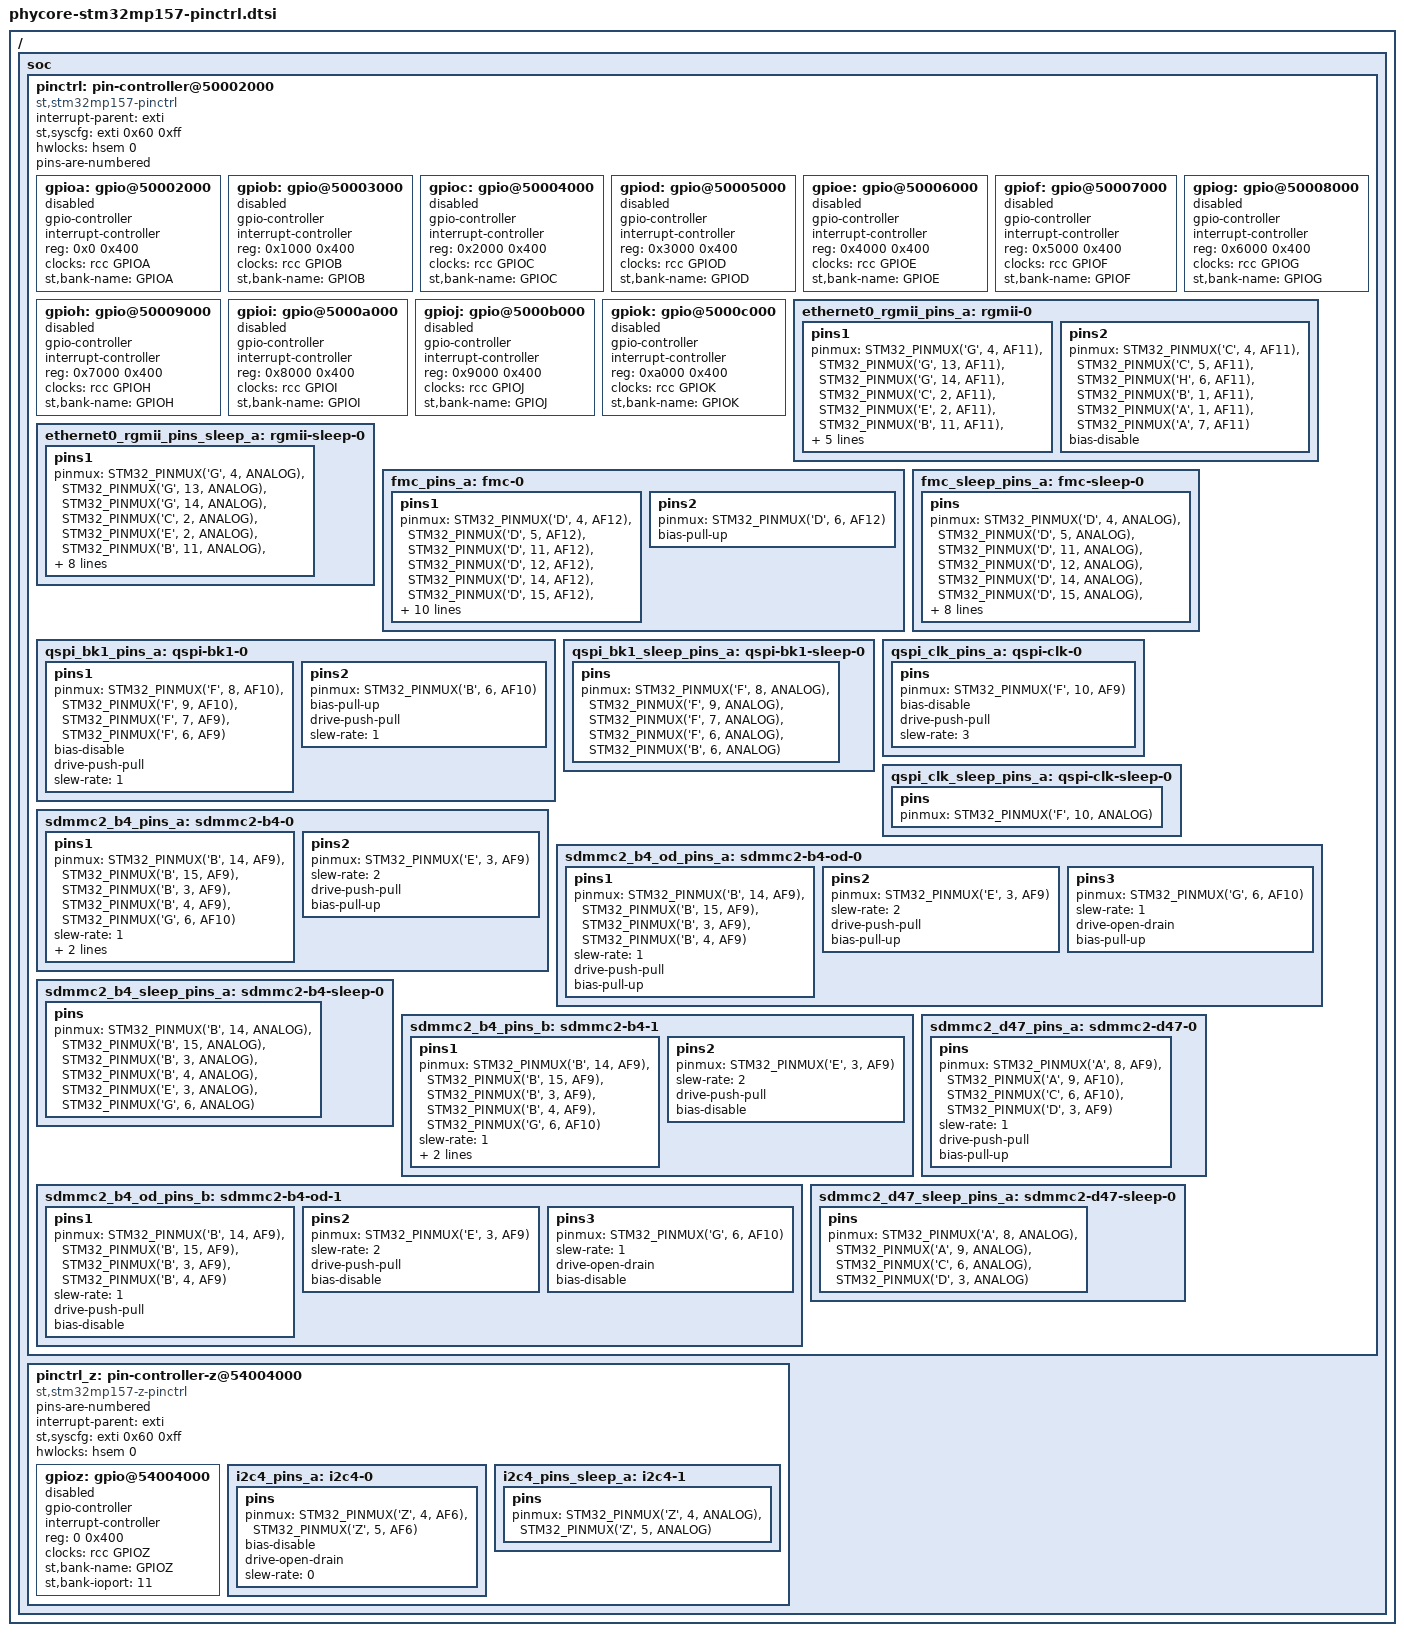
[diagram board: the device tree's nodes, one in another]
// SPDX-License-Identifier: (GPL-2.0+ OR BSD-3-Clause)
/*
 * Copyright (C) PHYTEC GmbH 2019-2020 - All Rights Reserved
 * Author: Dom VOVARD <dom.vovard@linrt.com>.
 */

#include <dt-bindings/pinctrl/stm32-pinfunc.h>

/ {
	soc {
		pinctrl: pin-controller@50002000 {
			#address-cells = <1>;
			#size-cells = <1>;
			compatible = "st,stm32mp157-pinctrl";
			ranges = <0 0x50002000 0xa400>;
			interrupt-parent = <&exti>;
			st,syscfg = <&exti 0x60 0xff>;
			hwlocks = <&hsem 0>;
			pins-are-numbered;

			gpioa: gpio@50002000 {
				gpio-controller;
				#gpio-cells = <2>;
				interrupt-controller;
				#interrupt-cells = <2>;
				reg = <0x0 0x400>;
				clocks = <&rcc GPIOA>;
				st,bank-name = "GPIOA";
				status = "disabled";
			};

			gpiob: gpio@50003000 {
				gpio-controller;
				#gpio-cells = <2>;
				interrupt-controller;
				#interrupt-cells = <2>;
				reg = <0x1000 0x400>;
				clocks = <&rcc GPIOB>;
				st,bank-name = "GPIOB";
				status = "disabled";
			};

			gpioc: gpio@50004000 {
				gpio-controller;
				#gpio-cells = <2>;
				interrupt-controller;
				#interrupt-cells = <2>;
				reg = <0x2000 0x400>;
				clocks = <&rcc GPIOC>;
				st,bank-name = "GPIOC";
				status = "disabled";
			};

			gpiod: gpio@50005000 {
				gpio-controller;
				#gpio-cells = <2>;
				interrupt-controller;
				#interrupt-cells = <2>;
				reg = <0x3000 0x400>;
				clocks = <&rcc GPIOD>;
				st,bank-name = "GPIOD";
				status = "disabled";
			};

			gpioe: gpio@50006000 {
				gpio-controller;
				#gpio-cells = <2>;
				interrupt-controller;
				#interrupt-cells = <2>;
				reg = <0x4000 0x400>;
				clocks = <&rcc GPIOE>;
				st,bank-name = "GPIOE";
				status = "disabled";
			};

			gpiof: gpio@50007000 {
				gpio-controller;
				#gpio-cells = <2>;
				interrupt-controller;
				#interrupt-cells = <2>;
				reg = <0x5000 0x400>;
				clocks = <&rcc GPIOF>;
				st,bank-name = "GPIOF";
				status = "disabled";
			};

			gpiog: gpio@50008000 {
				gpio-controller;
				#gpio-cells = <2>;
				interrupt-controller;
				#interrupt-cells = <2>;
				reg = <0x6000 0x400>;
				clocks = <&rcc GPIOG>;
				st,bank-name = "GPIOG";
				status = "disabled";
			};

			gpioh: gpio@50009000 {
				gpio-controller;
				#gpio-cells = <2>;
				interrupt-controller;
				#interrupt-cells = <2>;
				reg = <0x7000 0x400>;
				clocks = <&rcc GPIOH>;
				st,bank-name = "GPIOH";
				status = "disabled";
			};

			gpioi: gpio@5000a000 {
				gpio-controller;
				#gpio-cells = <2>;
				interrupt-controller;
				#interrupt-cells = <2>;
				reg = <0x8000 0x400>;
				clocks = <&rcc GPIOI>;
				st,bank-name = "GPIOI";
				status = "disabled";
			};

			gpioj: gpio@5000b000 {
				gpio-controller;
				#gpio-cells = <2>;
				interrupt-controller;
				#interrupt-cells = <2>;
				reg = <0x9000 0x400>;
				clocks = <&rcc GPIOJ>;
				st,bank-name = "GPIOJ";
				status = "disabled";
			};

			gpiok: gpio@5000c000 {
				gpio-controller;
				#gpio-cells = <2>;
				interrupt-controller;
				#interrupt-cells = <2>;
				reg = <0xa000 0x400>;
				clocks = <&rcc GPIOK>;
				st,bank-name = "GPIOK";
				status = "disabled";
			};

			ethernet0_rgmii_pins_a: rgmii-0 {
				pins1 {
					pinmux = <STM32_PINMUX('G', 4, AF11)>, /* ETH_RGMII_GTX_CLK */
						 <STM32_PINMUX('G', 13, AF11)>, /* ETH_RGMII_TXD0 */
						 <STM32_PINMUX('G', 14, AF11)>, /* ETH_RGMII_TXD1 */
						 <STM32_PINMUX('C', 2, AF11)>, /* ETH_RGMII_TXD2 */
						 <STM32_PINMUX('E', 2, AF11)>, /* ETH_RGMII_TXD3 */
						 <STM32_PINMUX('B', 11, AF11)>, /* ETH_RGMII_TX_CTL */
						 <STM32_PINMUX('A', 2, AF11)>, /* ETH_MDIO */
						 <STM32_PINMUX('C', 1, AF11)>; /* ETH_MDC */
					bias-disable;
					drive-push-pull;
					slew-rate = <2>;
				};
				pins2 {
					pinmux = <STM32_PINMUX('C', 4, AF11)>, /* ETH_RGMII_RXD0 */
						 <STM32_PINMUX('C', 5, AF11)>, /* ETH_RGMII_RXD1 */
						 <STM32_PINMUX('H', 6, AF11)>, /* ETH_RGMII_RXD2 */
						 <STM32_PINMUX('B', 1, AF11)>, /* ETH_RGMII_RXD3 */
						 <STM32_PINMUX('A', 1, AF11)>, /* ETH_RGMII_RX_CLK */
						 <STM32_PINMUX('A', 7, AF11)>; /* ETH_RGMII_RX_CTL */
					bias-disable;
				};
			};

			ethernet0_rgmii_pins_sleep_a: rgmii-sleep-0 {
				pins1 {
					pinmux = <STM32_PINMUX('G', 4, ANALOG)>, /* ETH_RGMII_GTX_CLK */
						 <STM32_PINMUX('G', 13, ANALOG)>, /* ETH_RGMII_TXD0 */
						 <STM32_PINMUX('G', 14, ANALOG)>, /* ETH_RGMII_TXD1 */
						 <STM32_PINMUX('C', 2, ANALOG)>, /* ETH_RGMII_TXD2 */
						 <STM32_PINMUX('E', 2, ANALOG)>, /* ETH_RGMII_TXD3 */
						 <STM32_PINMUX('B', 11, ANALOG)>, /* ETH_RGMII_TX_CTL */
						 <STM32_PINMUX('A', 2, ANALOG)>, /* ETH_MDIO */
						 <STM32_PINMUX('C', 1, ANALOG)>, /* ETH_MDC */
						 <STM32_PINMUX('C', 4, ANALOG)>, /* ETH_RGMII_RXD0 */
						 <STM32_PINMUX('C', 5, ANALOG)>, /* ETH_RGMII_RXD1 */
						 <STM32_PINMUX('H', 6, ANALOG)>, /* ETH_RGMII_RXD2 */
						 <STM32_PINMUX('B', 1, ANALOG)>, /* ETH_RGMII_RXD3 */
						 <STM32_PINMUX('A', 1, ANALOG)>, /* ETH_RGMII_RX_CLK */
						 <STM32_PINMUX('A', 7, ANALOG)>; /* ETH_RGMII_RX_CTL */
				};
			};

			fmc_pins_a: fmc-0 {
				pins1 {
					pinmux = <STM32_PINMUX('D', 4, AF12)>, /* FMC_NOE */
						 <STM32_PINMUX('D', 5, AF12)>, /* FMC_NWE */
						 <STM32_PINMUX('D', 11, AF12)>, /* FMC_A16_FMC_CLE */
						 <STM32_PINMUX('D', 12, AF12)>, /* FMC_A17_FMC_ALE */
						 <STM32_PINMUX('D', 14, AF12)>, /* FMC_D0 */
						 <STM32_PINMUX('D', 15, AF12)>, /* FMC_D1 */
						 <STM32_PINMUX('D', 0, AF12)>, /* FMC_D2 */
						 <STM32_PINMUX('D', 1, AF12)>, /* FMC_D3 */
						 <STM32_PINMUX('E', 7, AF12)>, /* FMC_D4 */
						 <STM32_PINMUX('E', 8, AF12)>, /* FMC_D5 */
						 <STM32_PINMUX('E', 9, AF12)>, /* FMC_D6 */
						 <STM32_PINMUX('E', 10, AF12)>, /* FMC_D7 */
						 <STM32_PINMUX('G', 9, AF12)>; /* FMC_NE2_FMC_NCE */
					bias-disable;
					drive-push-pull;
					slew-rate = <1>;
				};
				pins2 {
					pinmux = <STM32_PINMUX('D', 6, AF12)>; /* FMC_NWAIT */
					bias-pull-up;
				};
			};

			fmc_sleep_pins_a: fmc-sleep-0 {
				pins {
					pinmux = <STM32_PINMUX('D', 4, ANALOG)>, /* FMC_NOE */
						 <STM32_PINMUX('D', 5, ANALOG)>, /* FMC_NWE */
						 <STM32_PINMUX('D', 11, ANALOG)>, /* FMC_A16_FMC_CLE */
						 <STM32_PINMUX('D', 12, ANALOG)>, /* FMC_A17_FMC_ALE */
						 <STM32_PINMUX('D', 14, ANALOG)>, /* FMC_D0 */
						 <STM32_PINMUX('D', 15, ANALOG)>, /* FMC_D1 */
						 <STM32_PINMUX('D', 0, ANALOG)>, /* FMC_D2 */
						 <STM32_PINMUX('D', 1, ANALOG)>, /* FMC_D3 */
						 <STM32_PINMUX('E', 7, ANALOG)>, /* FMC_D4 */
						 <STM32_PINMUX('E', 8, ANALOG)>, /* FMC_D5 */
						 <STM32_PINMUX('E', 9, ANALOG)>, /* FMC_D6 */
						 <STM32_PINMUX('E', 10, ANALOG)>, /* FMC_D7 */
						 <STM32_PINMUX('D', 6, ANALOG)>, /* FMC_NWAIT */
						 <STM32_PINMUX('G', 9, ANALOG)>; /* FMC_NE2_FMC_NCE */
				};
			};

			qspi_bk1_pins_a: qspi-bk1-0 {
				pins1 {
					pinmux = <STM32_PINMUX('F', 8, AF10)>, /* QSPI_BK1_IO0 */
						 <STM32_PINMUX('F', 9, AF10)>, /* QSPI_BK1_IO1 */
						 <STM32_PINMUX('F', 7, AF9)>, /* QSPI_BK1_IO2 */
						 <STM32_PINMUX('F', 6, AF9)>; /* QSPI_BK1_IO3 */
					bias-disable;
					drive-push-pull;
					slew-rate = <1>;
				};
				pins2 {
					pinmux = <STM32_PINMUX('B', 6, AF10)>; /* QSPI_BK1_NCS */
					bias-pull-up;
					drive-push-pull;
					slew-rate = <1>;
				};
			};

			qspi_bk1_sleep_pins_a: qspi-bk1-sleep-0 {
				pins {
					pinmux = <STM32_PINMUX('F', 8, ANALOG)>, /* QSPI_BK1_IO0 */
						 <STM32_PINMUX('F', 9, ANALOG)>, /* QSPI_BK1_IO1 */
						 <STM32_PINMUX('F', 7, ANALOG)>, /* QSPI_BK1_IO2 */
						 <STM32_PINMUX('F', 6, ANALOG)>, /* QSPI_BK1_IO3 */
						 <STM32_PINMUX('B', 6, ANALOG)>; /* QSPI_BK1_NCS */
				};
			};

			qspi_clk_pins_a: qspi-clk-0 {
				pins {
					pinmux = <STM32_PINMUX('F', 10, AF9)>; /* QSPI_CLK */
					bias-disable;
					drive-push-pull;
					slew-rate = <3>;
				};
			};

			qspi_clk_sleep_pins_a: qspi-clk-sleep-0 {
				pins {
					pinmux = <STM32_PINMUX('F', 10, ANALOG)>; /* QSPI_CLK */
				};
			};

			sdmmc2_b4_pins_a: sdmmc2-b4-0 {
				pins1 {
					pinmux = <STM32_PINMUX('B', 14, AF9)>, /* SDMMC2_D0 */
						 <STM32_PINMUX('B', 15, AF9)>, /* SDMMC2_D1 */
						 <STM32_PINMUX('B', 3, AF9)>, /* SDMMC2_D2 */
						 <STM32_PINMUX('B', 4, AF9)>, /* SDMMC2_D3 */
						 <STM32_PINMUX('G', 6, AF10)>; /* SDMMC2_CMD */
					slew-rate = <1>;
					drive-push-pull;
					bias-pull-up;
				};
				pins2 {
					pinmux = <STM32_PINMUX('E', 3, AF9)>; /* SDMMC2_CK */
					slew-rate = <2>;
					drive-push-pull;
					bias-pull-up;
				};
			};

			sdmmc2_b4_od_pins_a: sdmmc2-b4-od-0 {
				pins1 {
					pinmux = <STM32_PINMUX('B', 14, AF9)>, /* SDMMC2_D0 */
						 <STM32_PINMUX('B', 15, AF9)>, /* SDMMC2_D1 */
						 <STM32_PINMUX('B', 3, AF9)>, /* SDMMC2_D2 */
						 <STM32_PINMUX('B', 4, AF9)>; /* SDMMC2_D3 */
					slew-rate = <1>;
					drive-push-pull;
					bias-pull-up;
				};
				pins2 {
					pinmux = <STM32_PINMUX('E', 3, AF9)>; /* SDMMC2_CK */
					slew-rate = <2>;
					drive-push-pull;
					bias-pull-up;
				};
				pins3 {
					pinmux = <STM32_PINMUX('G', 6, AF10)>; /* SDMMC2_CMD */
					slew-rate = <1>;
					drive-open-drain;
					bias-pull-up;
				};
			};

			sdmmc2_b4_sleep_pins_a: sdmmc2-b4-sleep-0 {
				pins {
					pinmux = <STM32_PINMUX('B', 14, ANALOG)>, /* SDMMC2_D0 */
						 <STM32_PINMUX('B', 15, ANALOG)>, /* SDMMC2_D1 */
						 <STM32_PINMUX('B', 3, ANALOG)>, /* SDMMC2_D2 */
						 <STM32_PINMUX('B', 4, ANALOG)>, /* SDMMC2_D3 */
						 <STM32_PINMUX('E', 3, ANALOG)>, /* SDMMC2_CK */
						 <STM32_PINMUX('G', 6, ANALOG)>; /* SDMMC2_CMD */
				};
			};

			sdmmc2_b4_pins_b: sdmmc2-b4-1 {
				pins1 {
					pinmux = <STM32_PINMUX('B', 14, AF9)>, /* SDMMC2_D0 */
						 <STM32_PINMUX('B', 15, AF9)>, /* SDMMC2_D1 */
						 <STM32_PINMUX('B', 3, AF9)>, /* SDMMC2_D2 */
						 <STM32_PINMUX('B', 4, AF9)>, /* SDMMC2_D3 */
						 <STM32_PINMUX('G', 6, AF10)>; /* SDMMC2_CMD */
					slew-rate = <1>;
					drive-push-pull;
					bias-disable;
				};
				pins2 {
					pinmux = <STM32_PINMUX('E', 3, AF9)>; /* SDMMC2_CK */
					slew-rate = <2>;
					drive-push-pull;
					bias-disable;
				};
			};

			sdmmc2_b4_od_pins_b: sdmmc2-b4-od-1 {
				pins1 {
					pinmux = <STM32_PINMUX('B', 14, AF9)>, /* SDMMC2_D0 */
						 <STM32_PINMUX('B', 15, AF9)>, /* SDMMC2_D1 */
						 <STM32_PINMUX('B', 3, AF9)>, /* SDMMC2_D2 */
						 <STM32_PINMUX('B', 4, AF9)>; /* SDMMC2_D3 */
					slew-rate = <1>;
					drive-push-pull;
					bias-disable;
				};
				pins2 {
					pinmux = <STM32_PINMUX('E', 3, AF9)>; /* SDMMC2_CK */
					slew-rate = <2>;
					drive-push-pull;
					bias-disable;
				};
				pins3 {
					pinmux = <STM32_PINMUX('G', 6, AF10)>; /* SDMMC2_CMD */
					slew-rate = <1>;
					drive-open-drain;
					bias-disable;
				};
			};

			sdmmc2_d47_pins_a: sdmmc2-d47-0 {
				pins {
					pinmux = <STM32_PINMUX('A', 8, AF9)>, /* SDMMC2_D4 */
						 <STM32_PINMUX('A', 9, AF10)>, /* SDMMC2_D5 */
						 <STM32_PINMUX('C', 6, AF10)>, /* SDMMC2_D6 */
						 <STM32_PINMUX('D', 3, AF9)>; /* SDMMC2_D7 */
					slew-rate = <1>;
					drive-push-pull;
					bias-pull-up;
				};
			};

			sdmmc2_d47_sleep_pins_a: sdmmc2-d47-sleep-0 {
				pins {
					pinmux = <STM32_PINMUX('A', 8, ANALOG)>, /* SDMMC2_D4 */
						 <STM32_PINMUX('A', 9, ANALOG)>, /* SDMMC2_D5 */
						 <STM32_PINMUX('C', 6, ANALOG)>, /* SDMMC2_D6 */
						 <STM32_PINMUX('D', 3, ANALOG)>; /* SDMMC2_D7 */
				};
			};
		};

		pinctrl_z: pin-controller-z@54004000 {
			#address-cells = <1>;
			#size-cells = <1>;
			compatible = "st,stm32mp157-z-pinctrl";
			ranges = <0 0x54004000 0x400>;
			pins-are-numbered;
			interrupt-parent = <&exti>;
			st,syscfg = <&exti 0x60 0xff>;
			hwlocks = <&hsem 0>;

			gpioz: gpio@54004000 {
				gpio-controller;
				#gpio-cells = <2>;
				interrupt-controller;
				#interrupt-cells = <2>;
				reg = <0 0x400>;
				clocks = <&rcc GPIOZ>;
				st,bank-name = "GPIOZ";
				st,bank-ioport = <11>;
				status = "disabled";
			};

			i2c4_pins_a: i2c4-0 {
				pins {
					pinmux = <STM32_PINMUX('Z', 4, AF6)>, /* I2C4_SCL */
						 <STM32_PINMUX('Z', 5, AF6)>; /* I2C4_SDA */
					bias-disable;
					drive-open-drain;
					slew-rate = <0>;
				};
			};

			i2c4_pins_sleep_a: i2c4-1 {
				pins {
					pinmux = <STM32_PINMUX('Z', 4, ANALOG)>, /* I2C4_SCL */
						 <STM32_PINMUX('Z', 5, ANALOG)>; /* I2C4_SDA */
				};
			};
		};
	};
};
